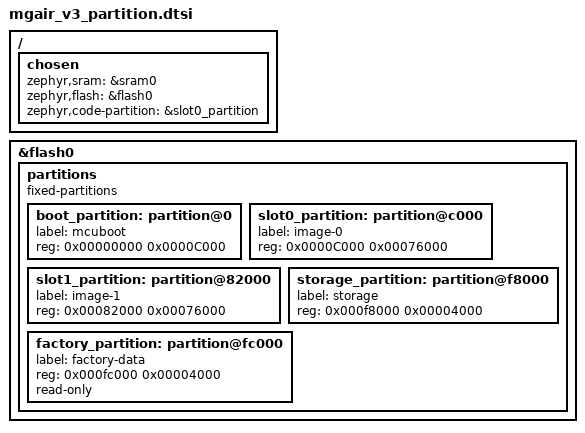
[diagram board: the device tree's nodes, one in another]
/*
 * Copyright (c) 2024 Jacob Winther
 *
 * SPDX-License-Identifier: Apache-2.0
 */

/ {
	chosen {
		zephyr,sram = &sram0;
		zephyr,flash = &flash0;
		zephyr,code-partition = &slot0_partition;
	};
};

&flash0 {
	partitions {
		compatible = "fixed-partitions";
		#address-cells = <1>;
		#size-cells = <1>;

		boot_partition: partition@0 {
			label = "mcuboot";
			reg = <0x00000000 0x0000C000>;
		};

		slot0_partition: partition@c000 {
			label = "image-0";
			reg = <0x0000C000 0x00076000>;
		};

		slot1_partition: partition@82000 {
			label = "image-1";
			reg = <0x00082000 0x00076000>;
		};

		/*
		 * Storage partition: 16KB
		 * Used by NVS (UID, Picklock)
		 * Address: 0xF8000 - 0xFC000
		 */
		storage_partition: partition@f8000 {
			label = "storage";
			reg = <0x000f8000 0x00004000>;
		};

		/*
		 * Factory Data partition: 16KB
		 * Used for RAW Read of Keys, Certs, MAC
		 * Address: 0xFC000 - End of Flash
		 */
		factory_partition: partition@fc000 {
			label = "factory-data";
			reg = <0x000fc000 0x00004000>;
			read-only; /* Zabezpieczenie przed przypadkowym zapisem przez aplikację */
		};
	};
};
